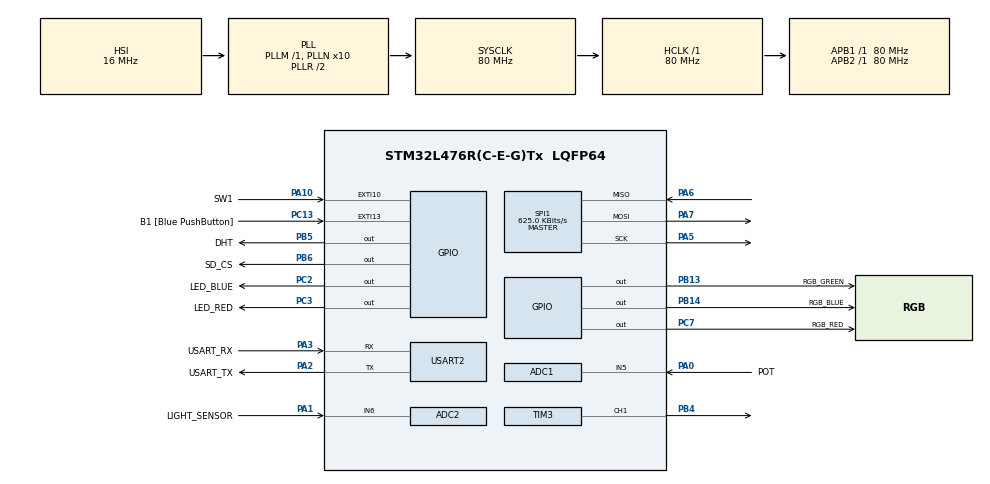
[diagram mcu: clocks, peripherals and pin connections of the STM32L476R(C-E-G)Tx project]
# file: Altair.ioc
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ADC1.Channel-0\#ChannelRegularConversion=ADC_CHANNEL_5
ADC1.NbrOfConversionFlag=1
ADC1.OffsetNumber-0\#ChannelRegularConversion=ADC_OFFSET_NONE
ADC1.Rank-0\#ChannelRegularConversion=1
ADC1.SamplingTime-0\#ChannelRegularConversion=ADC_SAMPLETIME_2CYCLES_5
ADC1.master=1
ADC2.Channel-0\#ChannelRegularConversion=ADC_CHANNEL_6
ADC2.NbrOfConversionFlag=1
ADC2.OffsetNumber-0\#ChannelRegularConversion=ADC_OFFSET_NONE
ADC2.Rank-0\#ChannelRegularConversion=1
ADC2.Resolution=ADC_RESOLUTION_8B
ADC2.SamplingTime-0\#ChannelRegularConversion=ADC_SAMPLETIME_2CYCLES_5
FREERTOS.Tasks01=defaultTask,24,128,StartDefaultTask,Default,NULL,Dynamic,NULL,NULL
FREERTOS.configTOTAL_HEAP_SIZE=60000
Mcu.Family=STM32L4
Mcu.Name=STM32L476R(C-E-G)Tx
Mcu.Package=LQFP64
NVIC.EXTI15_10_IRQn=true\:5\:0\:false\:false\:true\:true\:true\:true\:true
NVIC.PriorityGroup=NVIC_PRIORITYGROUP_4
NVIC.USART2_IRQn=true\:5\:0\:false\:false\:true\:true\:true\:true\:true
PA0.GPIO_Label=POT
PA0.Signal=ADCx_IN5
PA1.GPIO_Label=LIGHT_SENSOR
PA1.Signal=ADCx_IN6
PA10.GPIO_Label=SW1
PA10.Signal=GPXTI10
PA13\ (JTMS-SWDIO).GPIO_Label=TMS
PA13\ (JTMS-SWDIO).Mode=Serial_Wire
PA13\ (JTMS-SWDIO).Signal=SYS_JTMS-SWDIO
PA14\ (JTCK-SWCLK).GPIO_Label=TCK
PA14\ (JTCK-SWCLK).Mode=Serial_Wire
PA14\ (JTCK-SWCLK).Signal=SYS_JTCK-SWCLK
PA2.GPIO_Label=USART_TX
PA2.GPIO_Mode=GPIO_MODE_AF_PP
PA2.GPIO_PuPd=GPIO_NOPULL
PA2.GPIO_Speed=GPIO_SPEED_FREQ_VERY_HIGH
PA2.Mode=Asynchronous
PA2.Signal=USART2_TX
PA3.GPIO_Label=USART_RX
PA3.GPIO_Mode=GPIO_MODE_AF_PP
PA3.GPIO_PuPd=GPIO_NOPULL
PA3.GPIO_Speed=GPIO_SPEED_FREQ_VERY_HIGH
PA3.Mode=Asynchronous
PA3.Signal=USART2_RX
PA5.Mode=Full_Duplex_Master
PA5.Signal=SPI1_SCK
PA6.Mode=Full_Duplex_Master
PA6.Signal=SPI1_MISO
PA7.Mode=Full_Duplex_Master
PA7.Signal=SPI1_MOSI
PB13.GPIO_Label=RGB_GREEN
PB13.Signal=GPIO_Output
PB14.GPIO_Label=RGB_BLUE
PB14.Signal=GPIO_Output
PB3\ (JTDO-TRACESWO).GPIO_Label=SWO
PB3\ (JTDO-TRACESWO).Signal=SYS_JTDO-SWO
PB4\ (NJTRST).Signal=S_TIM3_CH1
PB5.GPIO_Label=DHT
PB5.Signal=GPIO_Output
PB6.GPIO_Label=SD_CS
PB6.Signal=GPIO_Output
PC13.GPIO_Label=B1 [Blue PushButton]
PC13.GPIO_ModeDefaultEXTI=GPIO_MODE_IT_FALLING
PC13.GPIO_PuPd=GPIO_NOPULL
PC13.Signal=GPXTI13
PC14-OSC32_IN\ (PC14).Mode=LSE-External-Oscillator
PC14-OSC32_IN\ (PC14).Signal=RCC_OSC32_IN
PC15-OSC32_OUT\ (PC15).Mode=LSE-External-Oscillator
PC15-OSC32_OUT\ (PC15).Signal=RCC_OSC32_OUT
PC2.GPIO_Label=LED_BLUE
PC2.Signal=GPIO_Output
PC3.GPIO_Label=LED_RED
PC3.Signal=GPIO_Output
PC7.GPIO_Label=RGB_RED
PC7.Signal=GPIO_Output
PH0-OSC_IN\ (PH0).Signal=RCC_OSC_IN
PH1-OSC_OUT\ (PH1).Signal=RCC_OSC_OUT
ProjectManager.HeapSize=0x200
ProjectManager.StackSize=0x400
ProjectManager.TargetToolchain=STM32CubeIDE
RCC.ADCFreq_Value=64000000
RCC.AHBFreq_Value=80000000
RCC.APB1Freq_Value=80000000
RCC.APB1TimFreq_Value=80000000
RCC.APB2Freq_Value=80000000
RCC.APB2TimFreq_Value=80000000
RCC.CortexFreq_Value=80000000
RCC.HCLKFreq_Value=80000000
RCC.HSE_VALUE=8000000
RCC.HSI_VALUE=16000000
RCC.MSI_VALUE=4000000
RCC.PLLN=10
RCC.PLLSourceVirtual=RCC_PLLSOURCE_HSI
RCC.PREFETCH_ENABLE=1
RCC.SYSCLKFreq_VALUE=80000000
RCC.SYSCLKSource=RCC_SYSCLKSOURCE_PLLCLK
RCC.USBFreq_Value=64000000
RCC.VCOOutputFreq_Value=160000000
SH.ADCx_IN5.0=ADC1_IN5,IN5-Single-Ended
SH.ADCx_IN6.0=ADC2_IN6,IN6-Single-Ended
SH.S_TIM3_CH1.0=TIM3_CH1,PWM Generation1 CH1
SPI1.BaudRatePrescaler=SPI_BAUDRATEPRESCALER_128
SPI1.CalculateBaudRate=625.0 KBits/s
SPI1.DataSize=SPI_DATASIZE_8BIT
SPI1.Direction=SPI_DIRECTION_2LINES
SPI1.Mode=SPI_MODE_MASTER
SPI1.VirtualType=VM_MASTER
TIM3.Channel-PWM\ Generation1\ CH1=TIM_CHANNEL_1
TIM3.Period=999
TIM3.Prescaler=179
TIM3.Pulse-PWM\ Generation1\ CH1=500
TIM6.Period=19999
TIM6.Prescaler=79
USART2.VirtualMode-Asynchronous=VM_ASYNC
VP_FATFS_VS_Generic.Mode=User_defined
VP_FREERTOS_VS_CMSIS_V2.Mode=CMSIS_V2
VP_RTC_VS_RTC_Activate.Mode=RTC_Enabled
VP_RTC_VS_RTC_Calendar.Mode=RTC_Calendar
VP_TIM6_VS_ClockSourceINT.Mode=Enable_Timer
board=NUCLEO-L476RG

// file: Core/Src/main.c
/* USER CODE BEGIN Header */
/**
  ******************************************************************************
  * @file           : main.c
  * @brief          : Main program body
  ******************************************************************************
  * @attention
  *
  * Copyright (c) 2025 STMicroelectronics.
  * All rights reserved.
  *
  * This software is licensed under terms that can be found in the LICENSE file
  * in the root directory of this software component.
  * If no LICENSE file comes with this software, it is provided AS-IS.
  *
  ******************************************************************************
  */
/* USER CODE END Header */
#include "main.h"
#include "cmsis_os.h"
#include "adc.h"
#include "fatfs.h"
#include "rtc.h"
#include "spi.h"
#include "tim.h"
#include "usart.h"
#include "gpio.h"

/* USER CODE BEGIN Includes */
#include "tasks/init_altair_task.h"
/* USER CODE END Includes */

void SystemClock_Config(void);
void PeriphCommonClock_Config(void);
void MX_FREERTOS_Init(void);

int main(void)
{

  /* MCU Configuration--------------------------------------------------------*/

  /* Reset of all peripherals, Initializes the Flash interface and the Systick. */
  HAL_Init();

  /* Configure the system clock */
  SystemClock_Config();

  /* Configure the peripherals common clocks */
  PeriphCommonClock_Config();

  /* Initialize all configured peripherals */
  MX_GPIO_Init();
  MX_USART2_UART_Init();
  MX_FATFS_Init();
  MX_ADC1_Init();
  MX_ADC2_Init();
  MX_SPI1_Init();
  MX_TIM3_Init();
  MX_RTC_Init();
  MX_TIM6_Init();
  /* USER CODE BEGIN 2 */
  const osThreadAttr_t altairTask = {
      .name = "MyTask",
      .stack_size = 128 * 4 * 16,  // Stack size in bytes (128 words)
      .priority = osPriorityNormal,  // Thread priority
  };

  osThreadId_t initTask = osThreadNew(init_altair, NULL, &altairTask);

  /* USER CODE END 2 */

  /* Init scheduler */
  osKernelInitialize();

  /* Call init function for freertos objects (in cmsis_os2.c) */
  MX_FREERTOS_Init();

  /* Start scheduler */
  osKernelStart();

  /* We should never get here as control is now taken by the scheduler */

  /* Infinite loop */
  while (1)
  {

  }
}

void SystemClock_Config(void)
{
  RCC_OscInitTypeDef RCC_OscInitStruct = {0};
  RCC_ClkInitTypeDef RCC_ClkInitStruct = {0};

  /** Configure the main internal regulator output voltage
  */
  if (HAL_PWREx_ControlVoltageScaling(PWR_REGULATOR_VOLTAGE_SCALE1) != HAL_OK)
  {
    Error_Handler();
  }

  /** Initializes the RCC Oscillators according to the specified parameters
  * in the RCC_OscInitTypeDef structure.
  */
  RCC_OscInitStruct.OscillatorType = RCC_OSCILLATORTYPE_HSI|RCC_OSCILLATORTYPE_LSI;
  RCC_OscInitStruct.HSIState = RCC_HSI_ON;
  RCC_OscInitStruct.HSICalibrationValue = RCC_HSICALIBRATION_DEFAULT;
  RCC_OscInitStruct.LSIState = RCC_LSI_ON;
  RCC_OscInitStruct.PLL.PLLState = RCC_PLL_ON;
  RCC_OscInitStruct.PLL.PLLSource = RCC_PLLSOURCE_HSI;
  RCC_OscInitStruct.PLL.PLLM = 1;
  RCC_OscInitStruct.PLL.PLLN = 10;
  RCC_OscInitStruct.PLL.PLLP = RCC_PLLP_DIV7;
  RCC_OscInitStruct.PLL.PLLQ = RCC_PLLQ_DIV2;
  RCC_OscInitStruct.PLL.PLLR = RCC_PLLR_DIV2;
  if (HAL_RCC_OscConfig(&RCC_OscInitStruct) != HAL_OK)
  {
    Error_Handler();
  }

  /** Initializes the CPU, AHB and APB buses clocks
  */
  RCC_ClkInitStruct.ClockType = RCC_CLOCKTYPE_HCLK|RCC_CLOCKTYPE_SYSCLK
                              |RCC_CLOCKTYPE_PCLK1|RCC_CLOCKTYPE_PCLK2;
  RCC_ClkInitStruct.SYSCLKSource = RCC_SYSCLKSOURCE_PLLCLK;
  RCC_ClkInitStruct.AHBCLKDivider = RCC_SYSCLK_DIV1;
  RCC_ClkInitStruct.APB1CLKDivider = RCC_HCLK_DIV1;
  RCC_ClkInitStruct.APB2CLKDivider = RCC_HCLK_DIV1;

  if (HAL_RCC_ClockConfig(&RCC_ClkInitStruct, FLASH_LATENCY_4) != HAL_OK)
  {
    Error_Handler();
  }
}

void PeriphCommonClock_Config(void)
{
  RCC_PeriphCLKInitTypeDef PeriphClkInit = {0};

  /** Initializes the peripherals clock
  */
  PeriphClkInit.PeriphClockSelection = RCC_PERIPHCLK_ADC;
  PeriphClkInit.AdcClockSelection = RCC_ADCCLKSOURCE_PLLSAI1;
  PeriphClkInit.PLLSAI1.PLLSAI1Source = RCC_PLLSOURCE_HSI;
  PeriphClkInit.PLLSAI1.PLLSAI1M = 1;
  PeriphClkInit.PLLSAI1.PLLSAI1N = 8;
  PeriphClkInit.PLLSAI1.PLLSAI1P = RCC_PLLP_DIV7;
  PeriphClkInit.PLLSAI1.PLLSAI1Q = RCC_PLLQ_DIV2;
  PeriphClkInit.PLLSAI1.PLLSAI1R = RCC_PLLR_DIV2;
  PeriphClkInit.PLLSAI1.PLLSAI1ClockOut = RCC_PLLSAI1_ADC1CLK;
  if (HAL_RCCEx_PeriphCLKConfig(&PeriphClkInit) != HAL_OK)
  {
    Error_Handler();
  }
}

void Error_Handler(void)
{
  __disable_irq();
  while (1)
  {
  }
}
